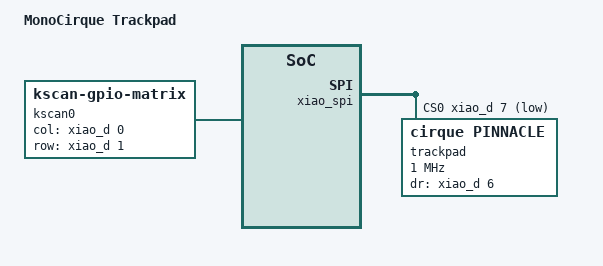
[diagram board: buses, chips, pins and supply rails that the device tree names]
/**
 * MonoCirque - Standalone Cirque Trackpad with Simple Gestures
 * Start with basic gesture support, minimal changes from your working config
 */

#include <dt-bindings/zmk/matrix_transform.h>

/ {
    model = "MonoCirque Trackpad";
    compatible = "zmk,generic-keyboard";

    chosen {
        zmk,kscan = &kscan0;
        zmk,matrix-transform = &default_transform;
    };

    default_transform: keymap_transform_0 {
        compatible = "zmk,matrix-transform";
        columns = <1>;
        rows = <1>;
        map = <RC(0,0)>;
    };

    /* Minimal dummy kscan - required by ZMK but not physically connected */
    kscan0: kscan {
        compatible = "zmk,kscan-gpio-matrix";
        wakeup-source;
        col-gpios = <&xiao_d 0 GPIO_ACTIVE_HIGH>;
        row-gpios = <&xiao_d 1 (GPIO_ACTIVE_HIGH | GPIO_PULL_DOWN)>;
    };

    /* Trackpad input listener - exactly like your original for now */
    trackpad_listener {
        compatible = "zmk,input-listener";
        device = <&trackpad>;
       
        /* Base: Normal cursor movement with 2x speed */
        input-processors = <&zip_xy_scaler 2 1>;
       
        /* Scroll mode - activated by layer switching */
        scroll_mode {
            layers = <1>;
            input-processors = <&zip_xy_to_scroll_mapper>;
        };
    };
};

/* Cirque Trackpad SPI Configuration - exactly like your original */
&xiao_spi {
    status = "okay";
    cs-gpios = <&xiao_d 7 GPIO_ACTIVE_LOW>;
   
    trackpad: trackpad@0 {
        compatible = "cirque,pinnacle";
        reg = <0>;
        spi-max-frequency = <1000000>;
        status = "okay";
        dr-gpios = <&xiao_d 6 (GPIO_ACTIVE_HIGH)>;
        sensitivity = "4x";
        sleep;
        y-invert;
        /* Enable taps - remove no-taps */
        /* no-taps; */
    };
};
